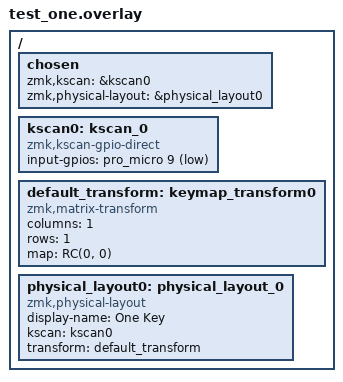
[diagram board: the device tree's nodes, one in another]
#include <dt-bindings/gpio/gpio.h>
#include <dt-bindings/zmk/matrix_transform.h>

/ {
    chosen {
        zmk,kscan = &kscan0;
        zmk,physical-layout = &physical_layout0;
    };

    kscan0: kscan_0 {
        compatible = "zmk,kscan-gpio-direct";
        input-gpios = <&pro_micro 9 (GPIO_ACTIVE_LOW | GPIO_PULL_UP)>;
    };

    default_transform: keymap_transform0 {
        compatible = "zmk,matrix-transform";
        columns = <1>;
        rows = <1>;
        map = <
            RC(0, 0)
        >;
    };

    physical_layout0: physical_layout_0 {
        compatible = "zmk,physical-layout";
        display-name = "One Key";
        kscan = <&kscan0>;
        transform = <&default_transform>;
    };
};
